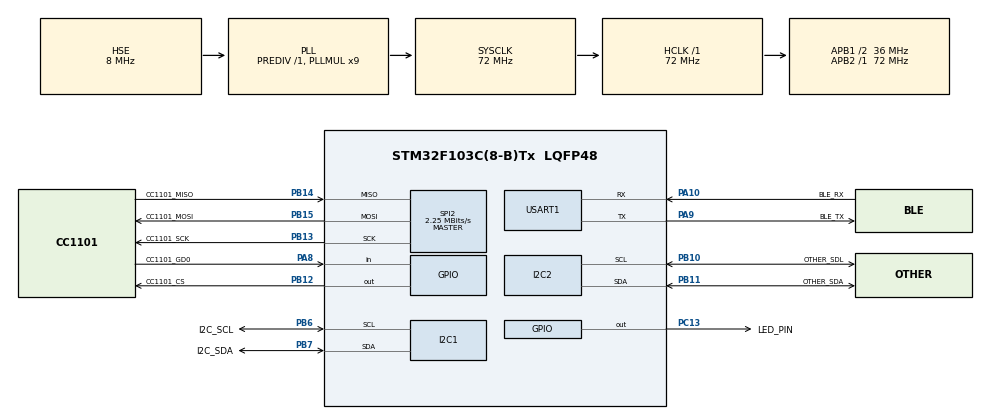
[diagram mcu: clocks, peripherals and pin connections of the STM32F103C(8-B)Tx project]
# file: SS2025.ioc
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I2C1.I2C_Mode=I2C_Fast
I2C2.I2C_Mode=I2C_Fast
Mcu.Family=STM32F1
Mcu.Name=STM32F103C(8-B)Tx
Mcu.Package=LQFP48
NVIC.PriorityGroup=NVIC_PRIORITYGROUP_4
NVIC.USART1_IRQn=true\:0\:0\:false\:false\:true\:true\:true\:true
PA10.GPIO_Label=BLE_RX
PA10.Mode=Asynchronous
PA10.Signal=USART1_RX
PA13.GPIO_Label=SWDIO
PA13.Mode=Serial_Wire
PA13.Signal=SYS_JTMS-SWDIO
PA14.GPIO_Label=SWCLK
PA14.Mode=Serial_Wire
PA14.Signal=SYS_JTCK-SWCLK
PA8.GPIO_Label=CC1101_GD0
PA8.Signal=GPIO_Input
PA9.GPIO_Label=BLE_TX
PA9.Mode=Asynchronous
PA9.Signal=USART1_TX
PB10.GPIO_Label=OTHER_SDL
PB10.Mode=I2C
PB10.Signal=I2C2_SCL
PB11.GPIO_Label=OTHER_SDA
PB11.Mode=I2C
PB11.Signal=I2C2_SDA
PB12.GPIO_Label=CC1101_CS
PB12.GPIO_Speed=GPIO_SPEED_FREQ_HIGH
PB12.PinState=GPIO_PIN_SET
PB12.Signal=GPIO_Output
PB13.GPIO_Label=CC1101_SCK
PB13.Mode=Full_Duplex_Master
PB13.Signal=SPI2_SCK
PB14.GPIO_Label=CC1101_MISO
PB14.GPIO_PuPd=GPIO_PULLUP
PB14.Mode=Full_Duplex_Master
PB14.Signal=SPI2_MISO
PB15.GPIO_Label=CC1101_MOSI
PB15.Mode=Full_Duplex_Master
PB15.Signal=SPI2_MOSI
PB6.GPIO_Label=I2C_SCL
PB6.Mode=I2C
PB6.Signal=I2C1_SCL
PB7.GPIO_Label=I2C_SDA
PB7.Mode=I2C
PB7.Signal=I2C1_SDA
PC13-TAMPER-RTC.GPIO_Label=LED_PIN
PC13-TAMPER-RTC.Signal=GPIO_Output
PD0-OSC_IN.Mode=HSE-External-Oscillator
PD0-OSC_IN.Signal=RCC_OSC_IN
PD1-OSC_OUT.Mode=HSE-External-Oscillator
PD1-OSC_OUT.Signal=RCC_OSC_OUT
ProjectManager.HeapSize=0x200
ProjectManager.StackSize=0x400
ProjectManager.TargetToolchain=STM32CubeIDE
RCC.AHBFreq_Value=72000000
RCC.APB1CLKDivider=RCC_HCLK_DIV2
RCC.APB1Freq_Value=36000000
RCC.APB1TimFreq_Value=72000000
RCC.APB2Freq_Value=72000000
RCC.APB2TimFreq_Value=72000000
RCC.HCLKFreq_Value=72000000
RCC.PLLMUL=RCC_PLL_MUL9
RCC.PLLSourceVirtual=RCC_PLLSOURCE_HSE
RCC.SYSCLKFreq_VALUE=72000000
RCC.SYSCLKSource=RCC_SYSCLKSOURCE_PLLCLK
RCC.USBFreq_Value=72000000
SPI2.BaudRatePrescaler=SPI_BAUDRATEPRESCALER_16
SPI2.CalculateBaudRate=2.25 MBits/s
SPI2.Direction=SPI_DIRECTION_2LINES
SPI2.Mode=SPI_MODE_MASTER
SPI2.VirtualType=VM_MASTER
USART1.Parity=PARITY_EVEN
USART1.VirtualMode=VM_ASYNC
USART1.WordLength=WORDLENGTH_9B
board=custom

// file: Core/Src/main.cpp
/* USER CODE BEGIN Header */
/**
  ******************************************************************************
  * @file           : main.c
  * @brief          : Main program body
  ******************************************************************************
  * @attention
  *
  * Copyright (c) 2025 STMicroelectronics.
  * All rights reserved.
  *
  * This software is licensed under terms that can be found in the LICENSE file
  * in the root directory of this software component.
  * If no LICENSE file comes with this software, it is provided AS-IS.
  *
  ******************************************************************************
  */
/* USER CODE END Header */
#include "main.h"
#include "i2c.h"
#include "spi.h"
#include "usart.h"
#include "gpio.h"

/* USER CODE BEGIN Includes */
#include <CC1101.h>
#include <GyroscopeV2.h>

/* USER CODE END Includes */

/* USER CODE BEGIN PTD */

#include <Logger.h>

void LOGGER(const char *text, uint8_t len)
{
    HAL_UART_Transmit(&huart1, (uint8_t *)text, len, 1000);
}

/* USER CODE END PTD */

/* USER CODE BEGIN PD */
using namespace IntroSatLib;

/** Создание класса гироскопа*/
GyroscopeV2 gyro(&hi2c1);

/* USER CODE END PD */

void SystemClock_Config(void);

/* USER CODE BEGIN 0 */

/** �?нициализация объектов для радио
IntroSatLib::intefaces::SPI spi(&hspi2);
IntroSatLib::intefaces::GPIO sck(CC1101_SCK_GPIO_Port, CC1101_SCK_Pin);
IntroSatLib::intefaces::GPIO mosi(CC1101_MOSI_GPIO_Port, CC1101_MOSI_Pin);
IntroSatLib::intefaces::GPIO miso(CC1101_MISO_GPIO_Port, CC1101_MISO_Pin);
IntroSatLib::intefaces::GPIO reset(CC1101_CS_GPIO_Port, CC1101_CS_Pin);
IntroSatLib::intefaces::GPIO gd0(CC1101_GD0_GPIO_Port, CC1101_GD0_Pin);
IntroSatLib::CC1101WithGD0 trans(spi, sck, mosi, miso, reset, gd0);
*/

/* USER CODE END 0 */

int main(void)
{

  /* MCU Configuration--------------------------------------------------------*/

  /* Reset of all peripherals, Initializes the Flash interface and the Systick. */
  HAL_Init();

  /* Configure the system clock */
  SystemClock_Config();

  /* Initialize all configured peripherals */
  MX_GPIO_Init();
  MX_I2C1_Init();
  MX_I2C2_Init();
  MX_SPI2_Init();
  MX_USART1_UART_Init();
  /* USER CODE BEGIN 2 */
//  trans.Init();
//  trans.setCCMode(1);          // set config for internal transmission mode.
//    trans.setModulation(0);      // set modulation mode. 0 = 2-FSK, 1 = GFSK, 2 = ASK/OOK, 3 = 4-FSK, 4 = MSK.
//    trans.setMHZ(433.92);        // Here you can set your basic frequency. The lib calculates the frequency automatically (default = 433.92).The cc1101 can: 300-348 MHZ, 387-464MHZ and 779-928MHZ. Read More info from datasheet.
//    trans.setDeviation(47.60);   // Set the Frequency deviation in kHz. Value from 1.58 to 380.85. Default is 47.60 kHz.
//    trans.setChannel(0);         // Set the Channelnumber from 0 to 255. Default is cahnnel 0.
//    trans.setChsp(199.95);       // The channel spacing is multiplied by the channel number CHAN and added to the base frequency in kHz. Value from 25.39 to 405.45. Default is 199.95 kHz.
//    trans.setRxBW(812.50);       // Set the Receive Bandwidth in kHz. Value from 58.03 to 812.50. Default is 812.50 kHz.
//    trans.setDRate(1);       // Set the Data Rate in kBaud. Value from 0.02 to 1621.83. Default is 99.97 kBaud!
//    trans.setPA(5);             // Set TxPower. The following settings are possible depending on the frequency band.  (-30  -20  -15  -10  -6    0    5    7    10   11   12) Default is max!
//    trans.setSyncMode(2);        // Combined sync-word qualifier mode. 0 = No preamble/sync. 1 = 16 sync word bits detected. 2 = 16/16 sync word bits detected. 3 = 30/32 sync word bits detected. 4 = No preamble/sync, carrier-sense above threshold. 5 = 15/16 + carrier-sense above threshold. 6 = 16/16 + carrier-sense above threshold. 7 = 30/32 + carrier-sense above threshold.
//    trans.setSyncWord(211, 145); // Set sync word. Must be the same for the transmitter and receiver. (Syncword high, Syncword low)
//    trans.setAdrChk(0);          // Controls address check configuration of received packages. 0 = No address check. 1 = Address check, no broadcast. 2 = Address check and 0 (0x00) broadcast. 3 = Address check and 0 (0x00) and 255 (0xFF) broadcast.
//    trans.setAddr(0);            // Address used for packet filtration. Optional broadcast addresses are 0 (0x00) and 255 (0xFF).
//    trans.setWhiteData(0);       // Turn data whitening on / off. 0 = Whitening off. 1 = Whitening on.
//    trans.setPktFormat(0);       // Format of RX and TX data. 0 = Normal mode, use FIFOs for RX and TX. 1 = Synchronous serial mode, Data in on GDO0 and data out on either of the GDOx pins. 2 = Random TX mode; sends random data using PN9 generator. Used for test. Works as normal mode, setting 0 (00), in RX. 3 = Asynchronous serial mode, Data in on GDO0 and data out on either of the GDOx pins.
//    trans.setLengthConfig(1);    // 0 = Fixed packet length mode. 1 = Variable packet length mode. 2 = Infinite packet length mode. 3 = Reserved
//    trans.setPacketLength(0);    // Indicates the packet length when fixed packet length mode is enabled. If variable packet length mode is used, this value indicates the maximum packet length allowed.
//    trans.setCrc(0);             // 1 = CRC calculation in TX and CRC check in RX enabled. 0 = CRC disabled for TX and RX.
//      trans.setCRC_AF(0);          // Enable automatic flush of RX FIFO when CRC is not OK. This requires that only one packet is in the RXIFIFO and that packet length is limited to the RX FIFO size.
//      trans.setDcFilterOff(0);     // Disable digital DC blocking filter before demodulator. Only for data rates ≤ 250 kBaud The recommended IF frequency changes when the DC blocking is disabled. 1 = Disable (current optimized). 0 = Enable (better sensitivity).
//      trans.setManchester(0);      // Enables Manchester encoding/decoding. 0 = Disable. 1 = Enable.
//      trans.setFEC(0);             // Enable Forward Error Correction (FEC) with interleaving for packet payload (Only supported for fixed packet length mode. 0 = Disable. 1 = Enable.
//      trans.setPRE(0);             // Sets the minimum number of preamble bytes to be transmitted. Values: 0 : 2, 1 : 3, 2 : 4, 3 : 6, 4 : 8, 5 : 12, 6 : 16, 7 : 24
//      trans.setPQT(0);             // Preamble quality estimator threshold. The preamble quality estimator increases an internal counter by one each time a bit is received that is different from the previous bit, and decreases the counter by 8 each time a bit is received that is the same as the last bit. A threshold of 4∙PQT for this counter is used to gate sync word detection. When PQT=0 a sync word is always accepted.
//      trans.setAppendStatus(0);    // When enabled, two status bytes will be appended to the payload of the packet. The status bytes contain RSSI and LQI values, as well as CRC OK.

  /* USER CODE END 2 */

  /* Infinite loop */
  /* USER CODE BEGIN WHILE */
  logText("KEK");
  gyro.Init();
  while (1)
  {
	  char ret[100] = { 0};
	  sprintf(ret, "x: %6d\ty: %6d\tz: %6d", gyro.RawX(), gyro.RawY(), gyro.RawZ());
	  logText(ret);
    /* USER CODE END WHILE */

  }
}

void SystemClock_Config(void)
{
  RCC_OscInitTypeDef RCC_OscInitStruct = {0};
  RCC_ClkInitTypeDef RCC_ClkInitStruct = {0};

  /** Initializes the RCC Oscillators according to the specified parameters
  * in the RCC_OscInitTypeDef structure.
  */
  RCC_OscInitStruct.OscillatorType = RCC_OSCILLATORTYPE_HSE;
  RCC_OscInitStruct.HSEState = RCC_HSE_ON;
  RCC_OscInitStruct.HSEPredivValue = RCC_HSE_PREDIV_DIV1;
  RCC_OscInitStruct.HSIState = RCC_HSI_ON;
  RCC_OscInitStruct.PLL.PLLState = RCC_PLL_ON;
  RCC_OscInitStruct.PLL.PLLSource = RCC_PLLSOURCE_HSE;
  RCC_OscInitStruct.PLL.PLLMUL = RCC_PLL_MUL9;
  if (HAL_RCC_OscConfig(&RCC_OscInitStruct) != HAL_OK)
  {
    Error_Handler();
  }

  /** Initializes the CPU, AHB and APB buses clocks
  */
  RCC_ClkInitStruct.ClockType = RCC_CLOCKTYPE_HCLK|RCC_CLOCKTYPE_SYSCLK
                              |RCC_CLOCKTYPE_PCLK1|RCC_CLOCKTYPE_PCLK2;
  RCC_ClkInitStruct.SYSCLKSource = RCC_SYSCLKSOURCE_PLLCLK;
  RCC_ClkInitStruct.AHBCLKDivider = RCC_SYSCLK_DIV1;
  RCC_ClkInitStruct.APB1CLKDivider = RCC_HCLK_DIV2;
  RCC_ClkInitStruct.APB2CLKDivider = RCC_HCLK_DIV1;

  if (HAL_RCC_ClockConfig(&RCC_ClkInitStruct, FLASH_LATENCY_2) != HAL_OK)
  {
    Error_Handler();
  }
}

void Error_Handler(void)
{
  __disable_irq();
  while (1)
  {
  }
}
